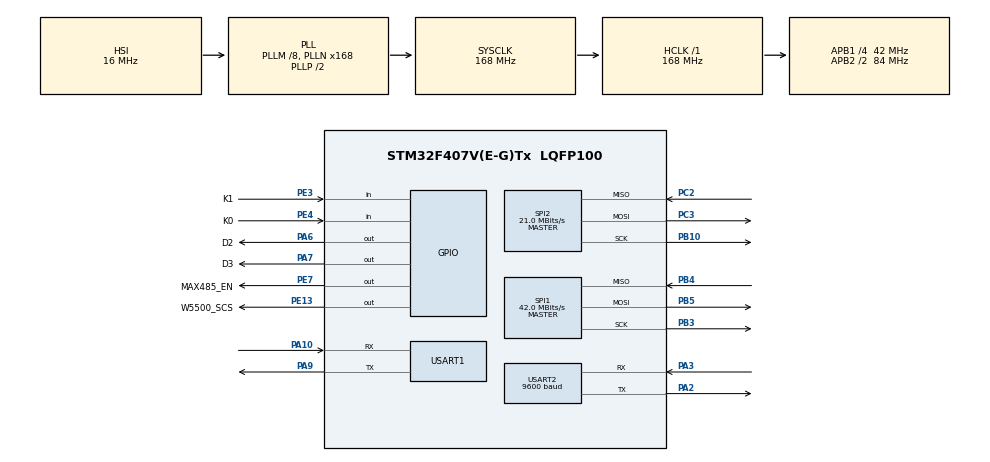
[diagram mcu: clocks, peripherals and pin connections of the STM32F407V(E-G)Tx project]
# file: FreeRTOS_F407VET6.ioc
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Dma.Request0=USART1_RX
Dma.Request1=USART1_TX
Dma.Request2=USART2_RX
Dma.Request3=USART2_TX
Dma.USART1_RX.0.Direction=DMA_PERIPH_TO_MEMORY
Dma.USART1_RX.0.FIFOMode=DMA_FIFOMODE_DISABLE
Dma.USART1_RX.0.Instance=DMA2_Stream2
Dma.USART1_RX.0.MemDataAlignment=DMA_MDATAALIGN_BYTE
Dma.USART1_RX.0.MemInc=DMA_MINC_ENABLE
Dma.USART1_RX.0.Mode=DMA_NORMAL
Dma.USART1_RX.0.PeriphDataAlignment=DMA_PDATAALIGN_BYTE
Dma.USART1_RX.0.PeriphInc=DMA_PINC_DISABLE
Dma.USART1_RX.0.Priority=DMA_PRIORITY_LOW
Dma.USART1_TX.1.Direction=DMA_MEMORY_TO_PERIPH
Dma.USART1_TX.1.FIFOMode=DMA_FIFOMODE_DISABLE
Dma.USART1_TX.1.Instance=DMA2_Stream7
Dma.USART1_TX.1.MemDataAlignment=DMA_MDATAALIGN_BYTE
Dma.USART1_TX.1.MemInc=DMA_MINC_ENABLE
Dma.USART1_TX.1.Mode=DMA_NORMAL
Dma.USART1_TX.1.PeriphDataAlignment=DMA_PDATAALIGN_BYTE
Dma.USART1_TX.1.PeriphInc=DMA_PINC_DISABLE
Dma.USART1_TX.1.Priority=DMA_PRIORITY_LOW
Dma.USART2_RX.2.Direction=DMA_PERIPH_TO_MEMORY
Dma.USART2_RX.2.FIFOMode=DMA_FIFOMODE_DISABLE
Dma.USART2_RX.2.Instance=DMA1_Stream5
Dma.USART2_RX.2.MemDataAlignment=DMA_MDATAALIGN_BYTE
Dma.USART2_RX.2.MemInc=DMA_MINC_ENABLE
Dma.USART2_RX.2.Mode=DMA_NORMAL
Dma.USART2_RX.2.PeriphDataAlignment=DMA_PDATAALIGN_BYTE
Dma.USART2_RX.2.PeriphInc=DMA_PINC_DISABLE
Dma.USART2_RX.2.Priority=DMA_PRIORITY_LOW
Dma.USART2_TX.3.Direction=DMA_MEMORY_TO_PERIPH
Dma.USART2_TX.3.FIFOMode=DMA_FIFOMODE_DISABLE
Dma.USART2_TX.3.Instance=DMA1_Stream6
Dma.USART2_TX.3.MemDataAlignment=DMA_MDATAALIGN_BYTE
Dma.USART2_TX.3.MemInc=DMA_MINC_ENABLE
Dma.USART2_TX.3.Mode=DMA_NORMAL
Dma.USART2_TX.3.PeriphDataAlignment=DMA_PDATAALIGN_BYTE
Dma.USART2_TX.3.PeriphInc=DMA_PINC_DISABLE
Dma.USART2_TX.3.Priority=DMA_PRIORITY_LOW
Mcu.Family=STM32F4
Mcu.Name=STM32F407V(E-G)Tx
Mcu.Package=LQFP100
NVIC.DMA1_Stream5_IRQn=true\:6\:0\:true\:false\:true\:false\:true\:true
NVIC.DMA1_Stream6_IRQn=true\:6\:0\:true\:false\:true\:false\:true\:true
NVIC.DMA2_Stream2_IRQn=true\:0\:0\:false\:false\:true\:false\:true\:true
NVIC.DMA2_Stream7_IRQn=true\:0\:0\:false\:false\:true\:false\:true\:true
NVIC.PriorityGroup=NVIC_PRIORITYGROUP_4
NVIC.TIM1_UP_TIM10_IRQn=true\:15\:0\:false\:false\:true\:false\:true\:true
NVIC.TimeBase=TIM1_UP_TIM10_IRQn
NVIC.TimeBaseIP=TIM1
NVIC.USART2_IRQn=true\:6\:0\:true\:false\:true\:true\:true\:true
PA10.Mode=Asynchronous
PA10.Signal=USART1_RX
PA13.Mode=Serial_Wire
PA13.Signal=SYS_JTMS-SWDIO
PA14.Mode=Serial_Wire
PA14.Signal=SYS_JTCK-SWCLK
PA2.Mode=Asynchronous
PA2.Signal=USART2_TX
PA3.Mode=Asynchronous
PA3.Signal=USART2_RX
PA6.GPIO_Label=D2
PA6.Signal=GPIO_Output
PA7.GPIO_Label=D3
PA7.Signal=GPIO_Output
PA9.Mode=Asynchronous
PA9.Signal=USART1_TX
PB10.Mode=Full_Duplex_Master
PB10.Signal=SPI2_SCK
PB3.Mode=Full_Duplex_Master
PB3.Signal=SPI1_SCK
PB4.Mode=Full_Duplex_Master
PB4.Signal=SPI1_MISO
PB5.Mode=Full_Duplex_Master
PB5.Signal=SPI1_MOSI
PC2.Mode=Full_Duplex_Master
PC2.Signal=SPI2_MISO
PC3.Mode=Full_Duplex_Master
PC3.Signal=SPI2_MOSI
PE13.GPIO_Label=W5500_SCS
PE13.PinState=GPIO_PIN_SET
PE13.Signal=GPIO_Output
PE3.GPIO_Label=K1
PE3.GPIO_PuPd=GPIO_PULLUP
PE3.Signal=GPIO_Input
PE4.GPIO_Label=K0
PE4.GPIO_PuPd=GPIO_PULLUP
PE4.Signal=GPIO_Input
PE7.GPIO_Label=MAX485_EN
PE7.Signal=GPIO_Output
PH0-OSC_IN.Mode=HSE-External-Oscillator
PH0-OSC_IN.Signal=RCC_OSC_IN
PH1-OSC_OUT.Mode=HSE-External-Oscillator
PH1-OSC_OUT.Signal=RCC_OSC_OUT
ProjectManager.HeapSize=0x200
ProjectManager.StackSize=0x400
ProjectManager.TargetToolchain=MDK-ARM V5.32
RCC.48MHZClocksFreq_Value=48000000
RCC.AHBFreq_Value=168000000
RCC.APB1CLKDivider=RCC_HCLK_DIV4
RCC.APB1Freq_Value=42000000
RCC.APB1TimFreq_Value=84000000
RCC.APB2CLKDivider=RCC_HCLK_DIV2
RCC.APB2Freq_Value=84000000
RCC.APB2TimFreq_Value=168000000
RCC.CortexFreq_Value=168000000
RCC.HCLKFreq_Value=168000000
RCC.HSE_VALUE=25000000
RCC.HSI_VALUE=16000000
RCC.LSE_VALUE=32768
RCC.PLLM=8
RCC.PLLN=168
RCC.PLLQ=7
RCC.SYSCLKFreq_VALUE=168000000
RCC.SYSCLKSource=RCC_SYSCLKSOURCE_PLLCLK
RCC.VCOOutputFreq_Value=336000000
SPI1.CalculateBaudRate=42.0 MBits/s
SPI1.Direction=SPI_DIRECTION_2LINES
SPI1.Mode=SPI_MODE_MASTER
SPI1.VirtualType=VM_MASTER
SPI2.CalculateBaudRate=21.0 MBits/s
SPI2.Direction=SPI_DIRECTION_2LINES
SPI2.Mode=SPI_MODE_MASTER
SPI2.VirtualType=VM_MASTER
USART1.VirtualMode=VM_ASYNC
USART2.BaudRate=9600
USART2.Parity=PARITY_NONE
USART2.VirtualMode=VM_ASYNC
USART2.WordLength=WORDLENGTH_8B
VP_SYS_VS_tim1.Mode=TIM1
board=custom

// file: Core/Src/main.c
/* USER CODE BEGIN Header */
/**
 ******************************************************************************
 * @file           : main.c
 * @brief          : Main program body
 ******************************************************************************
 * @attention
 *
 * Copyright (c) 2026 STMicroelectronics.
 * All rights reserved.
 *
 * This software is licensed under terms that can be found in the LICENSE file
 * in the root directory of this software component.
 * If no LICENSE file comes with this software, it is provided AS-IS.
 *
 ******************************************************************************
 */
/* USER CODE END Header */
#include "main.h"
#include "dma.h"
#include "spi.h"
#include "usart.h"
#include "gpio.h"

/* USER CODE BEGIN Includes */
#include "FreeRTOS.h"
#include "task.h"
#include "FreeRTOS_main.h"
#include "RS485.h"
/* USER CODE END Includes */

void SystemClock_Config(void);

int main(void)
{

  /* MCU Configuration--------------------------------------------------------*/

  /* Reset of all peripherals, Initializes the Flash interface and the Systick. */
  HAL_Init();

  /* Configure the system clock */
  SystemClock_Config();

  /* Initialize all configured peripherals */
  MX_GPIO_Init();
  MX_DMA_Init();
  MX_USART1_UART_Init();
  MX_USART2_UART_Init();
  MX_SPI1_Init();
  MX_SPI2_Init();
  /* USER CODE BEGIN 2 */
  RS485_Init();

  /* ↓↓↓ W5500 初始化：你自己在 W5500.c 里实现后在这里调用 ↓↓↓ */
  /* W5500_Init(); */

  /* 启动 FreeRTOS：内部会创建启动任务并调用 vTaskStartScheduler()，
     调度器一旦跑起来就不会再返回这里 */
  freertos_start();

  /* USER CODE END 2 */

  /* Infinite loop */
  while (1)
  {

  }
}

void SystemClock_Config(void)
{
  RCC_OscInitTypeDef RCC_OscInitStruct = {0};
  RCC_ClkInitTypeDef RCC_ClkInitStruct = {0};

  /** Configure the main internal regulator output voltage
   */
  __HAL_RCC_PWR_CLK_ENABLE();
  __HAL_PWR_VOLTAGESCALING_CONFIG(PWR_REGULATOR_VOLTAGE_SCALE1);

  /** Initializes the RCC Oscillators according to the specified parameters
   * in the RCC_OscInitTypeDef structure.
   */
  RCC_OscInitStruct.OscillatorType = RCC_OSCILLATORTYPE_HSI;
  RCC_OscInitStruct.HSIState = RCC_HSI_ON;
  RCC_OscInitStruct.HSICalibrationValue = RCC_HSICALIBRATION_DEFAULT;
  RCC_OscInitStruct.PLL.PLLState = RCC_PLL_ON;
  RCC_OscInitStruct.PLL.PLLSource = RCC_PLLSOURCE_HSI;
  RCC_OscInitStruct.PLL.PLLM = 8;
  RCC_OscInitStruct.PLL.PLLN = 168;
  RCC_OscInitStruct.PLL.PLLP = RCC_PLLP_DIV2;
  RCC_OscInitStruct.PLL.PLLQ = 7;
  if (HAL_RCC_OscConfig(&RCC_OscInitStruct) != HAL_OK)
  {
    Error_Handler();
  }

  /** Initializes the CPU, AHB and APB buses clocks
   */
  RCC_ClkInitStruct.ClockType = RCC_CLOCKTYPE_HCLK | RCC_CLOCKTYPE_SYSCLK | RCC_CLOCKTYPE_PCLK1 | RCC_CLOCKTYPE_PCLK2;
  RCC_ClkInitStruct.SYSCLKSource = RCC_SYSCLKSOURCE_PLLCLK;
  RCC_ClkInitStruct.AHBCLKDivider = RCC_SYSCLK_DIV1;
  RCC_ClkInitStruct.APB1CLKDivider = RCC_HCLK_DIV4;
  RCC_ClkInitStruct.APB2CLKDivider = RCC_HCLK_DIV2;

  if (HAL_RCC_ClockConfig(&RCC_ClkInitStruct, FLASH_LATENCY_5) != HAL_OK)
  {
    Error_Handler();
  }
}

/* USER CODE BEGIN 4 */

/*
 * FreeRTOS 钩子函数
 * FreeRTOSConfig.h 中打开了下面四个开关，就必须由用户提供对应实现，
 * 否则链接时会报 L6218E: Undefined symbol（heap_4.o / tasks.o 引用）。
 *
 *   configUSE_IDLE_HOOK              = 1  -> vApplicationIdleHook
 *   configUSE_TICK_HOOK              = 1  -> vApplicationTickHook
 *   configCHECK_FOR_STACK_OVERFLOW   = 2  -> vApplicationStackOverflowHook
 *   configUSE_MALLOC_FAILED_HOOK     = 1  -> vApplicationMallocFailedHook
 */

/* 空闲任务钩子：只在空闲任务运行时被调用。
   空闲任务优先级最低，这里是系统"没事干"的时候。
   不能在这里调用任何会阻塞的 API（vTaskDelay、带超时的队列等）。 */
void vApplicationIdleHook(void)
{
  /* 目前留空。以后可以在这里做低优先级后台工作，
     例如喂看门狗、统计 CPU 空闲率。 */
}

/* 系统节拍钩子：每发生一次 SysTick 中断就会调用一次。
   注意它运行在中断上下文，必须极短，禁止阻塞、禁止打印。 */
void vApplicationTickHook(void)
{
  /* 目前留空。 */
}

/* 栈溢出钩子：configCHECK_FOR_STACK_OVERFLOW = 2 时，
   任务切换过程中检测到栈越界就会进入这里。
   参数 pxTask 是越界任务的句柄，pcTaskName 是它的名字。 */
void vApplicationStackOverflowHook(TaskHandle_t pxTask, char *pcTaskName)
{
  (void)pxTask;
  (void)pcTaskName;

  /* 停在这里，用调试器看 pcTaskName 就能知道是哪个任务栈给小了。
     实际产品里应在这里复位或点亮故障灯。 */
  taskDISABLE_INTERRUPTS();
  for (;;)
  {
  }
}

/* 内存申请失败钩子：pvPortMalloc 返回 NULL 时调用。
   最常见的原因是 heap_4.c 里 ucHeap 数组开小了（configTOTAL_HEAP_SIZE）。 */
void vApplicationMallocFailedHook(void)
{
  taskDISABLE_INTERRUPTS();
  for (;;)
  {
  }
}

/* USER CODE END 4 */

void HAL_TIM_PeriodElapsedCallback(TIM_HandleTypeDef *htim)
{
  if (htim->Instance == TIM1)
  {
    HAL_IncTick();
  }
}

void Error_Handler(void)
{
  __disable_irq();
  while (1)
  {
  }
}
